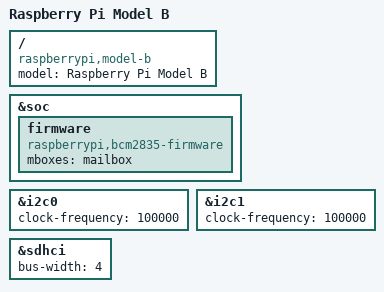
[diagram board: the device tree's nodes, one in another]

/include/ "bcm2835.dtsi"

/ {
	compatible = "raspberrypi,model-b", "brcm,bcm2835";
	model = "Raspberry Pi Model B";
};

&soc {
	firmware: firmware {
		compatible = "raspberrypi,bcm2835-firmware";
		mboxes = <&mailbox>;
	};
};

&i2c0 {
	status = "okay";
	clock-frequency = <100000>;
};

&i2c1 {
	status = "okay";
	clock-frequency = <100000>;
};

&sdhci {
	status = "okay";
	bus-width = <4>;
};
